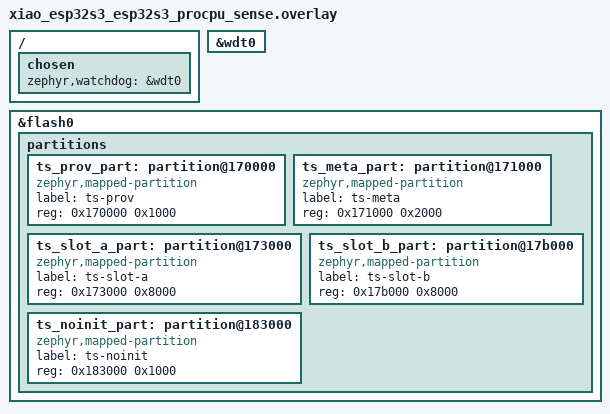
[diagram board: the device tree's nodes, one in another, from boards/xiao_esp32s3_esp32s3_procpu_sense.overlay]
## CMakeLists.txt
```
# SPDX-License-Identifier: Apache-2.0
cmake_minimum_required(VERSION 3.20.0)
find_package(Zephyr REQUIRED HINTS $ENV{ZEPHYR_BASE})
project(dsdbench)

target_sources(app PRIVATE src/main.c)
```

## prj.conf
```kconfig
# SPDX-License-Identifier: Apache-2.0
# dsdbench（MD1.2f）：D-SD demo 真机载体——SD 挂载 + ts-fs natives 全链。
CONFIG_PRINTK=y
CONFIG_TS_CORE=y
CONFIG_TS_SAFETY=y
CONFIG_TS_HAL=y
CONFIG_TS_HAL_FS=y
CONFIG_TS_STORE=y
CONFIG_TS_APP_WAMR=y
CONFIG_TS_TEST=y
CONFIG_MAIN_STACK_SIZE=8192
CONFIG_MAIN_THREAD_PRIORITY=15

# SD 卡栈（sdbench 同款：Sense 板载槽 spi2）
CONFIG_DISK_ACCESS=y
CONFIG_DISK_DRIVERS=y
CONFIG_DISK_DRIVER_SDMMC=y
CONFIG_SDHC=y
CONFIG_SPI_SDHC=y
CONFIG_SPI=y
CONFIG_FILE_SYSTEM=y
CONFIG_FAT_FILESYSTEM_ELM=y
CONFIG_FS_FATFS_LFN=y
CONFIG_LOG=y

# 看门狗（DEC-48 起常设）
CONFIG_WATCHDOG=y
CONFIG_TASK_WDT_HW_FALLBACK=y
CONFIG_TASK_WDT_MIN_TIMEOUT=5000
CONFIG_TASK_WDT_HW_FALLBACK_DELAY=5000
```

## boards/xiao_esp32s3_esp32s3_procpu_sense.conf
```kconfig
# dsdbench（MD1.2f）：内存形态 = wdtbench 同款（PSRAM 承 WAMR 堆；无网络面）。
CONFIG_ESP_SPIRAM=y
CONFIG_SPIRAM_MODE_OCT=y
CONFIG_ESP_SPIRAM_MEMTEST=y
CONFIG_TS_APP_PSRAM_HEAP=y
CONFIG_TS_APP_WAMR_HEAP=262144
CONFIG_TS_STORE_SLOT_SIZE=32768
CONFIG_TS_APP_LOAD_MAX=8192
CONFIG_HEAP_MEM_POOL_SIZE=131072
# 验签双区 scratch（DEC-49：payload ~2.7KB → 5616）
CONFIG_TS_VERIFY_SCRATCH=6144
# 4.5 复验批（同型防御）：verify 链在 4096 main 栈实测挂死（persistbench
# 实证——教训 31⑤ 同型）；8192 定值。
CONFIG_MAIN_STACK_SIZE=8192
```

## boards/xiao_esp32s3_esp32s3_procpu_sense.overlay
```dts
/*
 * dsdbench（MD1.2f）：ts-store flash 五分区（wdtbench 同款）+ esp32s3 硬件
 * 看门狗（DEC-48）。SD 槽 = Sense 板 DT 自带（spi2），无需追加。
 */

&wdt0 {
	status = "okay";
};

/ {
	chosen {
		zephyr,watchdog = &wdt0;
	};
};

/delete-node/ &slot1_partition;

&flash0 {
	partitions {
		ts_prov_part: partition@170000 {
			compatible = "zephyr,mapped-partition";
			label = "ts-prov";
			reg = <0x170000 0x1000>;
		};
		ts_meta_part: partition@171000 {
			compatible = "zephyr,mapped-partition";
			label = "ts-meta";
			reg = <0x171000 0x2000>;
		};
		ts_slot_a_part: partition@173000 {
			compatible = "zephyr,mapped-partition";
			label = "ts-slot-a";
			reg = <0x173000 0x8000>;
		};
		ts_slot_b_part: partition@17b000 {
			compatible = "zephyr,mapped-partition";
			label = "ts-slot-b";
			reg = <0x17b000 0x8000>;
		};
		ts_noinit_part: partition@183000 {
			compatible = "zephyr,mapped-partition";
			label = "ts-noinit";
			reg = <0x183000 0x1000>;
		};
	};
};
```

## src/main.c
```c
/* SPDX-License-Identifier: Apache-2.0 */
/* dsdbench（MD1.2f）：D-SD demo 真机载体——ts-fs natives 全链（DEC-47④⑤）。
 * 流程：挂载 SD（FAT，sdbench 同款）→ 建工作目录 → 安装 D-SD 包（机械生成
 * 头文件）→ ts_core_boot 装载 APP → APP 状态机（写/读回校验/白名单外拒绝/
 * 列目录/完成标记，[app1/l*] console 行）→ 宿主侧独立复核：
 *   ① dsd-done.txt 存在（APP 完成信号）
 *   ② dsd.txt 内容 = "DSD-" + 64 数字（独立读出逐字节验证）
 *   ③ /SD:/etc/dsd-deny.txt 不存在（白名单外写被拒的物理证据）
 * 判据（DS* console 行）：DS1 挂载 → DS2 安装 → DS3 ACTIVE → DS4 完成标记
 * → DS5 内容复核 → DS6 拒绝证据 → DS PASS。 */
#include <string.h>
#include <ff.h>
#include <zephyr/fs/fs.h>
#include <zephyr/kernel.h>
#include <zephyr/sys/printk.h>
#include <ts/appmgr.h>
#include <ts/core.h>

#include "dsd_pkg.h"

#define MNT "/SD:"
#define WORK_DIR MNT "/apps-data"
#define DATA_FILE WORK_DIR "/dsd.txt"
#define DONE_FILE WORK_DIR "/dsd-done.txt"
#define DENY_FILE MNT "/etc/dsd-deny.txt"

static const uint8_t root_pub[32]; /* TEST 语义验签（结构检查） */

static void watcher_thread(void *p1, void *p2, void *p3)
{
	ARG_UNUSED(p1);
	ARG_UNUSED(p2);
	ARG_UNUSED(p3);
	ts_app_info_t info;
	bool active_seen = false;

	for (int i = 0; i < 150; i++) {
		if (ts_appmgr_get_info(&info) == TS_OK &&
		    info.state == TS_APP_ACTIVE) {
			active_seen = true;
			break;
		}
		k_msleep(200);
	}
	if (!active_seen) {
		printk("DS FAIL no ACTIVE\n");
		return;
	}
	printk("DS3 APP ACTIVE app=%s\n", info.app_id);

	/* ① 完成标记（APP 第 5 步写） */
	bool done = false;

	for (int i = 0; i < 150; i++) {
		struct fs_dirent de;

		if (fs_stat(DONE_FILE, &de) == 0 && de.size >= 2) {
			done = true;
			break;
		}
		k_msleep(200);
	}
	if (!done) {
		printk("DS FAIL no done marker\n");
		return;
	}
	printk("DS4 done marker seen\n");

	/* ② 独立内容复核：dsd.txt = "DSD-" + 64 数字（共 68B） */
	static uint8_t rd[128];
	struct fs_file_t f;

	fs_file_t_init(&f);
	if (fs_open(&f, DATA_FILE, FS_O_READ) != 0) {
		printk("DS FAIL open data\n");
		return;
	}
	ssize_t n = fs_read(&f, rd, sizeof(rd));

	fs_close(&f);
	bool ok = (n == 68) && memcmp(rd, "DSD-", 4) == 0;

	for (int i = 4; ok && i < 68; i++) {
		if (rd[i] < '0' || rd[i] > '9') {
			ok = false;
		}
	}
	printk("DS5 data verify n=%d %s\n", (int)n, ok ? "OK" : "MISMATCH");
	if (!ok) {
		printk("DS FAIL content\n");
		return;
	}

	/* ③ 白名单外写拒绝的物理证据：deny 文件必须不存在 */
	struct fs_dirent de2;
	bool absent = fs_stat(DENY_FILE, &de2) != 0;

	printk("DS6 deny-file absent=%d（白名单外写被拒的物理证据）\n",
	       (int)absent);
	printk("%s\n", absent ? "DS PASS（写/读回/白名单拒绝/列目录全链）" :
	       "DS FAIL (deny file exists!)");
	for (;;) {
		k_sleep(K_SECONDS(10));
		printk("DS alive t=%u\n", (unsigned)k_uptime_get_32());
	}
}
K_THREAD_DEFINE(ds_tid, 4096, watcher_thread, NULL, NULL, NULL, 5, 0, 0);

int main(void)
{
	printk("DS0 dsdbench（MD1.2f：D-SD demo ts-fs 全链）\n");

	static FATFS fat;
	static struct fs_mount_t mp = {
		.type = FS_FATFS,
		.mnt_point = MNT,
		.fs_data = &fat,
	};
	int r = fs_mount(&mp);

	if (r != 0 && r != -EALREADY) {
		printk("DS FAIL mount r=%d\n", r);
		return 1;
	}
	fs_mkdir(WORK_DIR); /* APP 工作目录（-EEXIST 幂等） */
	printk("DS1 SD mounted%s\n", r == -EALREADY ? " (already)" : "");

	ts_app_info_t info;
	ts_res_t ir = ts_appmgr_install(dsd_pkg, sizeof(dsd_pkg), root_pub, &info);

	printk("DS2 install r=%d state=%d slot=%u\n",
	       (int)ir, (int)info.state, info.active_slot);
	if (ir != TS_OK) {
		printk("DS FAIL install\n");
		return 1;
	}
	ts_core_boot(); /* noreturn：装载 APP → ts-fs natives 状态机 */
	return 0;
}
```
